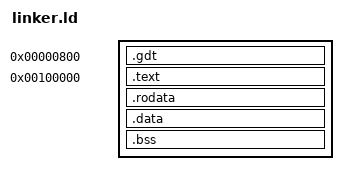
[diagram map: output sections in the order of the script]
ENTRY(_start)

SECTIONS {
    .gdt 0x800 :
    {
        *(.gdt)
    }

    . = 1M;

    .text : {
        *(.multiboot)
        *(.text)
    }

    .rodata : {
        *(.rodata)
    }

    .data : {
        *(.data)
    }

    .bss : {
        *(.bss)
    }

    /DISCARD/ : {
        *(.eh_frame)
        *(.comment)
    }
}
